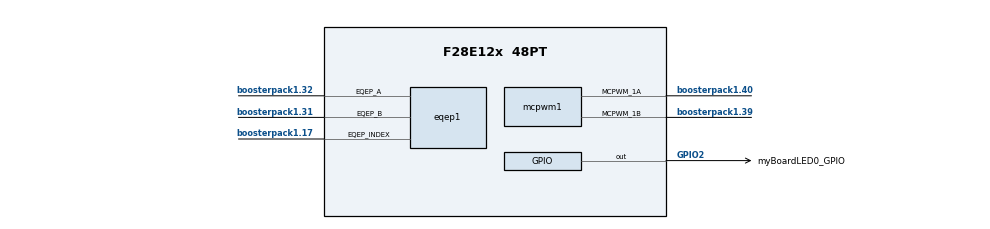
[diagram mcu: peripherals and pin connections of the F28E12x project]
/**
 * @cliArgs --board "/boards/LAUNCHXL_F28E12X" --device "F28E12x" --part "F28E12x_48PT" --package "48PT" --context "system" --product "C2000WARE@6.00.00.00"
 * @versions {"tool":"1.24.0+4109"}
 */

/**
 * Import the modules used in this configuration.
 */
const eqep   = scripting.addModule("/driverlib/eqep.js", {}, false);
const eqep1  = eqep.addInstance();
const gpio   = scripting.addModule("/driverlib/gpio.js", {}, false);
const gpio1  = gpio.addInstance();
const mcpwm  = scripting.addModule("/driverlib/mcpwm.js");
const mcpwm1 = mcpwm.addInstance();

/**
 * Write custom configuration values to the imported modules.
 */
eqep1.$name                      = "myEQEP1";
eqep1.eqepResolution             = "EQEP_CONFIG_1X_RESOLUTION";
eqep1.positionCounterMax         = 3999;
eqep1.latchPositionCounter       = "EQEP_LATCH_UNIT_TIME_OUT";
eqep1.positionIndexEvents        = "EQEP_INIT_RISING_INDEX";
eqep1.enableModule               = true;
eqep1.enableUnitTimer            = true;
eqep1.unitTimerPeriod            = 1200000;
eqep1.registerInterrupts         = true;
eqep1.enableInterrupt            = true;
eqep1.interruptSources           = ["EQEP_INT_UNIT_TIME_OUT"];
eqep1.emulationMode              = "EQEP_EMULATIONMODE_RUNFREE";
eqep1.useInterfacePins           = ["EQEP#_A","EQEP#_B","EQEP#_INDEX"];
eqep1.useCase                    = "NO STROBE";
eqep1.eqepInt.enableInterrupt    = true;
eqep1.eqep.eqep_aPin.$assign     = "boosterpack1.32";
eqep1.eqep.eqep_bPin.$assign     = "boosterpack1.31";
eqep1.eqep.eqep_indexPin.$assign = "boosterpack1.17";

gpio1.$name                    = "myBoardLED0_GPIO";
gpio1.direction                = "GPIO_DIR_MODE_OUT";
gpio1.writeInitialValue        = true;
gpio1.gpioPin.$assign          = "GPIO2";
gpio1.gpioPin["GPIO#"].$assign = "boosterpack1.38";

mcpwm.commentOutDefaultCode = true;

mcpwm1.$name                                                         = "myMCPWM0";
mcpwm1.mcpwmTimebase_period                                          = 24000;
mcpwm1.mcpwmTimebase_counterMode                                     = "MCPWM_COUNTER_MODE_UP_DOWN";
mcpwm1.mcpwmCounterCompare_cmpA                                      = 12000;
mcpwm1.mcpwmActionQualifier_MCPWM_AQ_OUTPUT_1A_ON_TIMEBASE_UP_CMPA   = "MCPWM_AQ_OUTPUT_HIGH";
mcpwm1.mcpwmActionQualifier_MCPWM_AQ_OUTPUT_1A_ON_TIMEBASE_DOWN_CMPA = "MCPWM_AQ_OUTPUT_LOW";
mcpwm1.mcpwmActionQualifier_MCPWM_AQ_OUTPUT_1B_ON_TIMEBASE_ZERO      = "MCPWM_AQ_OUTPUT_LOW";
mcpwm1.mcpwmActionQualifier_MCPWM_AQ_OUTPUT_1B_ON_TIMEBASE_PERIOD    = "MCPWM_AQ_OUTPUT_HIGH";
mcpwm1.useCase                                                       = "CUSTOM";
mcpwm1.useInterfacePins                                              = ["MCPWM#_1A","MCPWM#_1B"];
mcpwm1.mcpwm.$assign                                                 = "MCPWM1";
mcpwm1.mcpwm.mcpwm_1aPin.$assign                                     = "boosterpack1.40";
mcpwm1.mcpwm.mcpwm_1bPin.$assign                                     = "boosterpack1.39";
scripting.suppress("Connected to hardware,@@@.+?@@@ is connected to MCPWM BP on the LAUNCHXL-F28E12X\\. Consider selecting it in \'use hardware\' above\\. @@@.+?@@@", mcpwm1.mcpwm, "mcpwm_1aPin");
scripting.suppress("Connected to hardware,@@@.+?@@@ is connected to MCPWM BP on the LAUNCHXL-F28E12X\\. Consider selecting it in \'use hardware\' above\\. @@@.+?@@@", mcpwm1.mcpwm, "mcpwm_1bPin");
